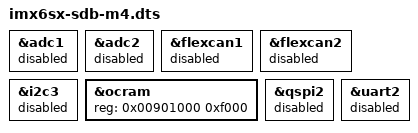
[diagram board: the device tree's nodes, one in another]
/*
 * Copyright (C) 2016 Freescale Semiconductor, Inc.
 *
 * This program is free software; you can redistribute it and/or modify
 * it under the terms of the GNU General Public License version 2 as
 * published by the Free Software Foundation.
 */

#include "imx6sx-sdb.dts"

/*
 * The following modules are manupulated by M4, should be disabled
 * at A7/Linux side
 * ADC1/2, FLEXCAN1/2, I2C3, QSPI2, UART2, WDOG3
 *
 */

&adc1 {
	status = "disabled";
};

&adc2 {
	status = "disabled";
};

&flexcan1 {
	status = "disabled";
};

&flexcan2 {
	status = "disabled";
};

&i2c3 {
	status = "disabled";
};

&ocram {
	reg = <0x00901000 0xf000>;
};

&qspi2 {
	status = "disabled";
};

&uart2 {
	status = "disabled";
};
